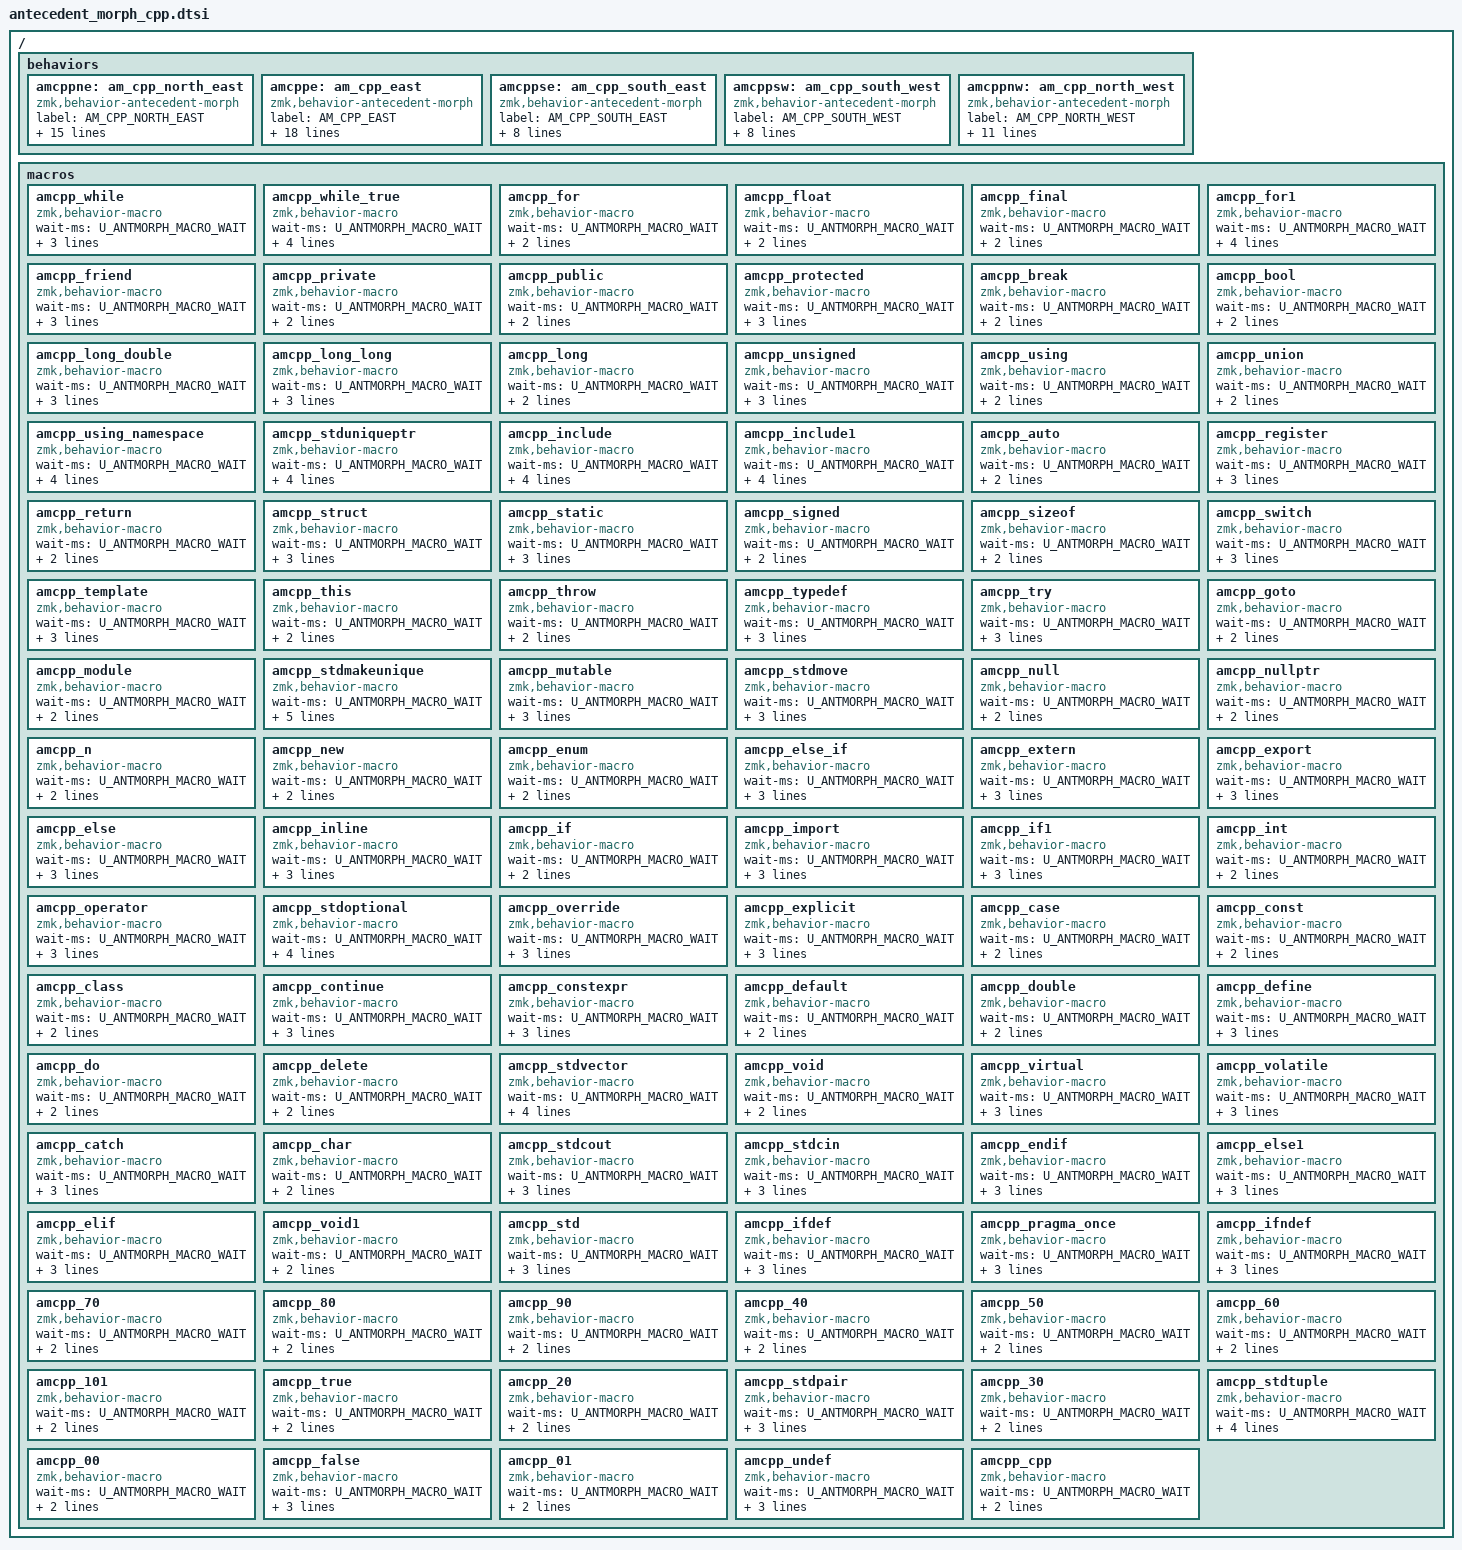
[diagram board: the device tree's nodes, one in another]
// Cpp schema version 1.2
// Automatically generated by ZMK Antecedent Morph Config Generator

/ {
    behaviors {
        // Base layer
        amcppne: am_cpp_north_east {
            compatible = "zmk,behavior-antecedent-morph";
            label = "AM_CPP_NORTH_EAST";
            #binding-cells = <0>;
            defaults = <&none>;
            bindings = <&amcpp_for>, <&amcpp_private>, <&amcpp_break>, <&amcpp_long_double>, <&amcpp_unsigned>, <&amcpp_include>, <&amcpp_register>, <&amcpp_struct>, <&amcpp_template>, <&amcpp_module>, <&amcpp_null>, <&amcpp_enum>, <&amcpp_inline>, <&amcpp_operator>, <&amcpp_case>, <&amcpp_default>, <&amcpp_stdvector>, <&kp N0>, <&amcpp_void1>, <&amcpp_ifdef>, <&amcpp_70>, <&amcpp_80>, <&amcpp_90>, <&amcpp_40>, <&amcpp_50>, <&amcpp_60>, <&amcpp_101>, <&amcpp_20>, <&amcpp_30>, <&amcpp_00>, <&amcpp_undef>;
            antecedents = <F P B L U APOS R S T M N E I O C D V DOT LPAR HASH N7 N8 N9 N4 N5 N6 N1 N2 N3 N0 SPACE>;
            max-delay-ms = <U_ANTMORPH_DELAY>;
        };
        amcppe: am_cpp_east {
            compatible = "zmk,behavior-antecedent-morph";
            label = "AM_CPP_EAST";
            #binding-cells = <0>;
            defaults = <&none>;
            bindings = <&amcpp_while>, <&amcpp_float>, <&amcpp_public>, <&amcpp_bool>, <&amcpp_long_long>, <&amcpp_using>, <&amcpp_auto>, <&amcpp_return>, <&amcpp_static>, <&amcpp_this>, <&amcpp_goto>, <&amcpp_stdmakeunique>, <&amcpp_nullptr>, <&amcpp_else_if>, <&amcpp_if>, <&amcpp_stdoptional>, <&amcpp_explicit>, <&amcpp_const>, <&amcpp_double>, <&amcpp_void>, <&amcpp_catch>, <&amcpp_stdcout>, <&amcpp_stdcin>, <&amcpp_else1>, <&kp RBRC>, <&kp RPAR>, <&kp EQUAL>, <&amcpp_std>, <&kp EQUAL>, <&kp EQUAL>, <&kp EQUAL>, <&kp EQUAL>, <&amcpp_pragma_once>, <&kp EQUAL>, <&kp EQUAL>, <&kp RBKT>, <&amcpp_true>, <&amcpp_stdpair>, <&amcpp_stdtuple>, <&amcpp_false>, <&kp EQUAL>, <&amcpp_cpp>;
            antecedents = <W F P B L U A R S T G M N E I O X C D V H COMMA DOT FSLH LBRC LPAR STAR COLON PRCNT CARET PLUS EXCL HASH PIPE AMPS LBKT N1 N2 N3 N0 MINUS SPACE>;
            max-delay-ms = <U_ANTMORPH_DELAY>;
        };
        amcppse: am_cpp_south_east {
            compatible = "zmk,behavior-antecedent-morph";
            label = "AM_CPP_SOUTH_EAST";
            #binding-cells = <0>;
            defaults = <&none>;
            bindings = <&amcpp_final>, <&amcpp_protected>, <&amcpp_union>, <&amcpp_signed>, <&amcpp_throw>, <&amcpp_mutable>, <&amcpp_extern>, <&amcpp_import>, <&amcpp_class>, <&amcpp_define>, <&amcpp_virtual>, <&amcpp_ifndef>, <&amcpp_01>;
            antecedents = <F P U S T M E I C D V HASH N0>;
            max-delay-ms = <U_ANTMORPH_DELAY>;
        };
        amcppsw: am_cpp_south_west {
            compatible = "zmk,behavior-antecedent-morph";
            label = "AM_CPP_SOUTH_WEST";
            #binding-cells = <0>;
            defaults = <&none>;
            bindings = <&amcpp_while_true>, <&amcpp_for1>, <&amcpp_using_namespace>, <&amcpp_sizeof>, <&amcpp_typedef>, <&amcpp_n>, <&amcpp_export>, <&amcpp_if1>, <&amcpp_continue>, <&amcpp_do>, <&amcpp_endif>, <&amcpp_elif>;
            antecedents = <W F U S T N E I C D DOT FSLH>;
            max-delay-ms = <U_ANTMORPH_DELAY>;
        };
        amcppnw: am_cpp_north_west {
            compatible = "zmk,behavior-antecedent-morph";
            label = "AM_CPP_NORTH_WEST";
            #binding-cells = <0>;
            defaults = <&none>;
            bindings = <&amcpp_friend>, <&amcpp_long>, <&amcpp_stduniqueptr>, <&amcpp_include1>, <&amcpp_switch>, <&amcpp_try>, <&amcpp_stdmove>, <&amcpp_new>, <&amcpp_else>, <&amcpp_int>, <&amcpp_override>, <&amcpp_constexpr>, <&amcpp_delete>, <&amcpp_volatile>, <&amcpp_char>, <&kp EQUAL>, <&kp EQUAL>, <&kp EQUAL>;
            antecedents = <F L U APOS S T M N E I O C D V H COMMA DOT FSLH>;
            max-delay-ms = <U_ANTMORPH_DELAY>;
        };
    };
    macros {
        amcpp_while: amcpp_while {
            compatible = "zmk,behavior-macro";
            #binding-cells = <0>;
            wait-ms = <U_ANTMORPH_MACRO_WAIT>;
            tap-ms = <U_ANTMORPH_MACRO_TAP>;
            // (w)hile (
            bindings = <&kp H &kp I &kp L &kp E &kp SPACE &kp LPAR>;
        };
        amcpp_while_true: amcpp_while_true {
            compatible = "zmk,behavior-macro";
            #binding-cells = <0>;
            wait-ms = <U_ANTMORPH_MACRO_WAIT>;
            tap-ms = <U_ANTMORPH_MACRO_TAP>;
            // (w)hile (true) {⏎
            bindings = <&kp H &kp I &kp L &kp E &kp SPACE &kp LPAR &kp T &kp R &kp U &kp E &kp RPAR &kp SPACE &kp LBRC &kp RET>;
        };
        amcpp_for: amcpp_for {
            compatible = "zmk,behavior-macro";
            #binding-cells = <0>;
            wait-ms = <U_ANTMORPH_MACRO_WAIT>;
            tap-ms = <U_ANTMORPH_MACRO_TAP>;
            // (f)or (
            bindings = <&kp O &kp R &kp SPACE &kp LPAR>;
        };
        amcpp_float: amcpp_float {
            compatible = "zmk,behavior-macro";
            #binding-cells = <0>;
            wait-ms = <U_ANTMORPH_MACRO_WAIT>;
            tap-ms = <U_ANTMORPH_MACRO_TAP>;
            // (f)loat
            bindings = <&kp L &kp O &kp A &kp T>;
        };
        amcpp_final: amcpp_final {
            compatible = "zmk,behavior-macro";
            #binding-cells = <0>;
            wait-ms = <U_ANTMORPH_MACRO_WAIT>;
            tap-ms = <U_ANTMORPH_MACRO_TAP>;
            // (f)inal
            bindings = <&kp I &kp N &kp A &kp L>;
        };
        amcpp_for1: amcpp_for1 {
            compatible = "zmk,behavior-macro";
            #binding-cells = <0>;
            wait-ms = <U_ANTMORPH_MACRO_WAIT>;
            tap-ms = <U_ANTMORPH_MACRO_TAP>;
            // (f)or (;;) {⏎
            bindings = <&kp O &kp R &kp SPACE &kp LPAR &kp SEMI &kp SEMI &kp RPAR &kp SPACE &kp LBRC &kp RET>;
        };
        amcpp_friend: amcpp_friend {
            compatible = "zmk,behavior-macro";
            #binding-cells = <0>;
            wait-ms = <U_ANTMORPH_MACRO_WAIT>;
            tap-ms = <U_ANTMORPH_MACRO_TAP>;
            // (f)riend 
            bindings = <&kp R &kp I &kp E &kp N &kp D &kp SPACE>;
        };
        amcpp_private: amcpp_private {
            compatible = "zmk,behavior-macro";
            #binding-cells = <0>;
            wait-ms = <U_ANTMORPH_MACRO_WAIT>;
            tap-ms = <U_ANTMORPH_MACRO_TAP>;
            // (p)rivate
            bindings = <&kp R &kp I &kp V &kp A &kp T &kp E>;
        };
        amcpp_public: amcpp_public {
            compatible = "zmk,behavior-macro";
            #binding-cells = <0>;
            wait-ms = <U_ANTMORPH_MACRO_WAIT>;
            tap-ms = <U_ANTMORPH_MACRO_TAP>;
            // (p)ublic
            bindings = <&kp U &kp B &kp L &kp I &kp C>;
        };
        amcpp_protected: amcpp_protected {
            compatible = "zmk,behavior-macro";
            #binding-cells = <0>;
            wait-ms = <U_ANTMORPH_MACRO_WAIT>;
            tap-ms = <U_ANTMORPH_MACRO_TAP>;
            // (p)rotected
            bindings = <&kp R &kp O &kp T &kp E &kp C &kp T &kp E &kp D>;
        };
        amcpp_break: amcpp_break {
            compatible = "zmk,behavior-macro";
            #binding-cells = <0>;
            wait-ms = <U_ANTMORPH_MACRO_WAIT>;
            tap-ms = <U_ANTMORPH_MACRO_TAP>;
            // (b)reak;
            bindings = <&kp R &kp E &kp A &kp K &kp SEMI>;
        };
        amcpp_bool: amcpp_bool {
            compatible = "zmk,behavior-macro";
            #binding-cells = <0>;
            wait-ms = <U_ANTMORPH_MACRO_WAIT>;
            tap-ms = <U_ANTMORPH_MACRO_TAP>;
            // (b)ool
            bindings = <&kp O &kp O &kp L>;
        };
        amcpp_long_double: amcpp_long_double {
            compatible = "zmk,behavior-macro";
            #binding-cells = <0>;
            wait-ms = <U_ANTMORPH_MACRO_WAIT>;
            tap-ms = <U_ANTMORPH_MACRO_TAP>;
            // (l)ong double
            bindings = <&kp O &kp N &kp G &kp SPACE &kp D &kp O &kp U &kp B &kp L &kp E>;
        };
        amcpp_long_long: amcpp_long_long {
            compatible = "zmk,behavior-macro";
            #binding-cells = <0>;
            wait-ms = <U_ANTMORPH_MACRO_WAIT>;
            tap-ms = <U_ANTMORPH_MACRO_TAP>;
            // (l)ong long
            bindings = <&kp O &kp N &kp G &kp SPACE &kp L &kp O &kp N &kp G>;
        };
        amcpp_long: amcpp_long {
            compatible = "zmk,behavior-macro";
            #binding-cells = <0>;
            wait-ms = <U_ANTMORPH_MACRO_WAIT>;
            tap-ms = <U_ANTMORPH_MACRO_TAP>;
            // (l)ong
            bindings = <&kp O &kp N &kp G>;
        };
        amcpp_unsigned: amcpp_unsigned {
            compatible = "zmk,behavior-macro";
            #binding-cells = <0>;
            wait-ms = <U_ANTMORPH_MACRO_WAIT>;
            tap-ms = <U_ANTMORPH_MACRO_TAP>;
            // (u)nsigned
            bindings = <&kp N &kp S &kp I &kp G &kp N &kp E &kp D>;
        };
        amcpp_using: amcpp_using {
            compatible = "zmk,behavior-macro";
            #binding-cells = <0>;
            wait-ms = <U_ANTMORPH_MACRO_WAIT>;
            tap-ms = <U_ANTMORPH_MACRO_TAP>;
            // (u)sing 
            bindings = <&kp S &kp I &kp N &kp G &kp SPACE>;
        };
        amcpp_union: amcpp_union {
            compatible = "zmk,behavior-macro";
            #binding-cells = <0>;
            wait-ms = <U_ANTMORPH_MACRO_WAIT>;
            tap-ms = <U_ANTMORPH_MACRO_TAP>;
            // (u)nion 
            bindings = <&kp N &kp I &kp O &kp N &kp SPACE>;
        };
        amcpp_using_namespace: amcpp_using_namespace {
            compatible = "zmk,behavior-macro";
            #binding-cells = <0>;
            wait-ms = <U_ANTMORPH_MACRO_WAIT>;
            tap-ms = <U_ANTMORPH_MACRO_TAP>;
            // (u)sing namespace 
            bindings = <&kp S &kp I &kp N &kp G &kp SPACE &kp N &kp A &kp M &kp E &kp S &kp P &kp A &kp C &kp E &kp SPACE>;
        };
        amcpp_stduniqueptr: amcpp_stduniqueptr {
            compatible = "zmk,behavior-macro";
            #binding-cells = <0>;
            wait-ms = <U_ANTMORPH_MACRO_WAIT>;
            tap-ms = <U_ANTMORPH_MACRO_TAP>;
            // [u]std::unique_ptr<
            bindings = <&kp BSPC &kp S &kp T &kp D &kp COLON &kp COLON &kp U &kp N &kp I &kp Q &kp U &kp E &kp UNDER &kp P &kp T &kp R &kp LT>;
        };
        amcpp_include: amcpp_include {
            compatible = "zmk,behavior-macro";
            #binding-cells = <0>;
            wait-ms = <U_ANTMORPH_MACRO_WAIT>;
            tap-ms = <U_ANTMORPH_MACRO_TAP>;
            // [‘]#include “”←
            bindings = <&kp BSPC &kp HASH &kp I &kp N &kp C &kp L &kp U &kp D &kp E &kp SPACE &kp DQT &kp DQT &kp LEFT>;
        };
        amcpp_include1: amcpp_include1 {
            compatible = "zmk,behavior-macro";
            #binding-cells = <0>;
            wait-ms = <U_ANTMORPH_MACRO_WAIT>;
            tap-ms = <U_ANTMORPH_MACRO_TAP>;
            // [‘]#include <>←
            bindings = <&kp BSPC &kp HASH &kp I &kp N &kp C &kp L &kp U &kp D &kp E &kp SPACE &kp LT &kp GT &kp LEFT>;
        };
        amcpp_auto: amcpp_auto {
            compatible = "zmk,behavior-macro";
            #binding-cells = <0>;
            wait-ms = <U_ANTMORPH_MACRO_WAIT>;
            tap-ms = <U_ANTMORPH_MACRO_TAP>;
            // (a)uto
            bindings = <&kp U &kp T &kp O>;
        };
        amcpp_register: amcpp_register {
            compatible = "zmk,behavior-macro";
            #binding-cells = <0>;
            wait-ms = <U_ANTMORPH_MACRO_WAIT>;
            tap-ms = <U_ANTMORPH_MACRO_TAP>;
            // (r)egister
            bindings = <&kp E &kp G &kp I &kp S &kp T &kp E &kp R>;
        };
        amcpp_return: amcpp_return {
            compatible = "zmk,behavior-macro";
            #binding-cells = <0>;
            wait-ms = <U_ANTMORPH_MACRO_WAIT>;
            tap-ms = <U_ANTMORPH_MACRO_TAP>;
            // (r)eturn
            bindings = <&kp E &kp T &kp U &kp R &kp N>;
        };
        amcpp_struct: amcpp_struct {
            compatible = "zmk,behavior-macro";
            #binding-cells = <0>;
            wait-ms = <U_ANTMORPH_MACRO_WAIT>;
            tap-ms = <U_ANTMORPH_MACRO_TAP>;
            // (s)truct 
            bindings = <&kp T &kp R &kp U &kp C &kp T &kp SPACE>;
        };
        amcpp_static: amcpp_static {
            compatible = "zmk,behavior-macro";
            #binding-cells = <0>;
            wait-ms = <U_ANTMORPH_MACRO_WAIT>;
            tap-ms = <U_ANTMORPH_MACRO_TAP>;
            // (s)tatic 
            bindings = <&kp T &kp A &kp T &kp I &kp C &kp SPACE>;
        };
        amcpp_signed: amcpp_signed {
            compatible = "zmk,behavior-macro";
            #binding-cells = <0>;
            wait-ms = <U_ANTMORPH_MACRO_WAIT>;
            tap-ms = <U_ANTMORPH_MACRO_TAP>;
            // (s)igned
            bindings = <&kp I &kp G &kp N &kp E &kp D>;
        };
        amcpp_sizeof: amcpp_sizeof {
            compatible = "zmk,behavior-macro";
            #binding-cells = <0>;
            wait-ms = <U_ANTMORPH_MACRO_WAIT>;
            tap-ms = <U_ANTMORPH_MACRO_TAP>;
            // (s)izeof
            bindings = <&kp I &kp Z &kp E &kp O &kp F>;
        };
        amcpp_switch: amcpp_switch {
            compatible = "zmk,behavior-macro";
            #binding-cells = <0>;
            wait-ms = <U_ANTMORPH_MACRO_WAIT>;
            tap-ms = <U_ANTMORPH_MACRO_TAP>;
            // (s)witch (
            bindings = <&kp W &kp I &kp T &kp C &kp H &kp SPACE &kp LPAR>;
        };
        amcpp_template: amcpp_template {
            compatible = "zmk,behavior-macro";
            #binding-cells = <0>;
            wait-ms = <U_ANTMORPH_MACRO_WAIT>;
            tap-ms = <U_ANTMORPH_MACRO_TAP>;
            // (t)emplate 
            bindings = <&kp E &kp M &kp P &kp L &kp A &kp T &kp E &kp SPACE>;
        };
        amcpp_this: amcpp_this {
            compatible = "zmk,behavior-macro";
            #binding-cells = <0>;
            wait-ms = <U_ANTMORPH_MACRO_WAIT>;
            tap-ms = <U_ANTMORPH_MACRO_TAP>;
            // (t)his
            bindings = <&kp H &kp I &kp S>;
        };
        amcpp_throw: amcpp_throw {
            compatible = "zmk,behavior-macro";
            #binding-cells = <0>;
            wait-ms = <U_ANTMORPH_MACRO_WAIT>;
            tap-ms = <U_ANTMORPH_MACRO_TAP>;
            // (t)hrow 
            bindings = <&kp H &kp R &kp O &kp W &kp SPACE>;
        };
        amcpp_typedef: amcpp_typedef {
            compatible = "zmk,behavior-macro";
            #binding-cells = <0>;
            wait-ms = <U_ANTMORPH_MACRO_WAIT>;
            tap-ms = <U_ANTMORPH_MACRO_TAP>;
            // (t)ypedef 
            bindings = <&kp Y &kp P &kp E &kp D &kp E &kp F &kp SPACE>;
        };
        amcpp_try: amcpp_try {
            compatible = "zmk,behavior-macro";
            #binding-cells = <0>;
            wait-ms = <U_ANTMORPH_MACRO_WAIT>;
            tap-ms = <U_ANTMORPH_MACRO_TAP>;
            // (t)ry {⏎
            bindings = <&kp R &kp Y &kp SPACE &kp LBRC &kp RET>;
        };
        amcpp_goto: amcpp_goto {
            compatible = "zmk,behavior-macro";
            #binding-cells = <0>;
            wait-ms = <U_ANTMORPH_MACRO_WAIT>;
            tap-ms = <U_ANTMORPH_MACRO_TAP>;
            // (g)oto 
            bindings = <&kp O &kp T &kp O &kp SPACE>;
        };
        amcpp_module: amcpp_module {
            compatible = "zmk,behavior-macro";
            #binding-cells = <0>;
            wait-ms = <U_ANTMORPH_MACRO_WAIT>;
            tap-ms = <U_ANTMORPH_MACRO_TAP>;
            // (m)odule
            bindings = <&kp O &kp D &kp U &kp L &kp E>;
        };
        amcpp_stdmakeunique: amcpp_stdmakeunique {
            compatible = "zmk,behavior-macro";
            #binding-cells = <0>;
            wait-ms = <U_ANTMORPH_MACRO_WAIT>;
            tap-ms = <U_ANTMORPH_MACRO_TAP>;
            // [m]std::make_unique<>(
            bindings = <&kp BSPC &kp S &kp T &kp D &kp COLON &kp COLON &kp M &kp A &kp K &kp E &kp UNDER &kp U &kp N &kp I &kp Q &kp U &kp E &kp LT &kp GT &kp LPAR>;
        };
        amcpp_mutable: amcpp_mutable {
            compatible = "zmk,behavior-macro";
            #binding-cells = <0>;
            wait-ms = <U_ANTMORPH_MACRO_WAIT>;
            tap-ms = <U_ANTMORPH_MACRO_TAP>;
            // (m)utable 
            bindings = <&kp U &kp T &kp A &kp B &kp L &kp E &kp SPACE>;
        };
        amcpp_stdmove: amcpp_stdmove {
            compatible = "zmk,behavior-macro";
            #binding-cells = <0>;
            wait-ms = <U_ANTMORPH_MACRO_WAIT>;
            tap-ms = <U_ANTMORPH_MACRO_TAP>;
            // [m]std::move(
            bindings = <&kp BSPC &kp S &kp T &kp D &kp COLON &kp COLON &kp M &kp O &kp V &kp E &kp LPAR>;
        };
        amcpp_null: amcpp_null {
            compatible = "zmk,behavior-macro";
            #binding-cells = <0>;
            wait-ms = <U_ANTMORPH_MACRO_WAIT>;
            tap-ms = <U_ANTMORPH_MACRO_TAP>;
            // (n)ULL
            bindings = <&kp LS(U) &kp LS(L) &kp LS(L)>;
        };
        amcpp_nullptr: amcpp_nullptr {
            compatible = "zmk,behavior-macro";
            #binding-cells = <0>;
            wait-ms = <U_ANTMORPH_MACRO_WAIT>;
            tap-ms = <U_ANTMORPH_MACRO_TAP>;
            // (n)ullptr
            bindings = <&kp U &kp L &kp L &kp P &kp T &kp R>;
        };
        amcpp_n: amcpp_n {
            compatible = "zmk,behavior-macro";
            #binding-cells = <0>;
            wait-ms = <U_ANTMORPH_MACRO_WAIT>;
            tap-ms = <U_ANTMORPH_MACRO_TAP>;
            // [n]\n
            bindings = <&kp BSPC &kp BSLH &kp N>;
        };
        amcpp_new: amcpp_new {
            compatible = "zmk,behavior-macro";
            #binding-cells = <0>;
            wait-ms = <U_ANTMORPH_MACRO_WAIT>;
            tap-ms = <U_ANTMORPH_MACRO_TAP>;
            // (n)ew
            bindings = <&kp E &kp W>;
        };
        amcpp_enum: amcpp_enum {
            compatible = "zmk,behavior-macro";
            #binding-cells = <0>;
            wait-ms = <U_ANTMORPH_MACRO_WAIT>;
            tap-ms = <U_ANTMORPH_MACRO_TAP>;
            // (e)num  
            bindings = <&kp N &kp U &kp M &kp SPACE &kp SPACE>;
        };
        amcpp_else_if: amcpp_else_if {
            compatible = "zmk,behavior-macro";
            #binding-cells = <0>;
            wait-ms = <U_ANTMORPH_MACRO_WAIT>;
            tap-ms = <U_ANTMORPH_MACRO_TAP>;
            // (e)lse if (
            bindings = <&kp L &kp S &kp E &kp SPACE &kp I &kp F &kp SPACE &kp LPAR>;
        };
        amcpp_extern: amcpp_extern {
            compatible = "zmk,behavior-macro";
            #binding-cells = <0>;
            wait-ms = <U_ANTMORPH_MACRO_WAIT>;
            tap-ms = <U_ANTMORPH_MACRO_TAP>;
            // (e)xtern 
            bindings = <&kp X &kp T &kp E &kp R &kp N &kp SPACE>;
        };
        amcpp_export: amcpp_export {
            compatible = "zmk,behavior-macro";
            #binding-cells = <0>;
            wait-ms = <U_ANTMORPH_MACRO_WAIT>;
            tap-ms = <U_ANTMORPH_MACRO_TAP>;
            // (e)xport 
            bindings = <&kp X &kp P &kp O &kp R &kp T &kp SPACE>;
        };
        amcpp_else: amcpp_else {
            compatible = "zmk,behavior-macro";
            #binding-cells = <0>;
            wait-ms = <U_ANTMORPH_MACRO_WAIT>;
            tap-ms = <U_ANTMORPH_MACRO_TAP>;
            // (e)lse {⏎
            bindings = <&kp L &kp S &kp E &kp SPACE &kp LBRC &kp RET>;
        };
        amcpp_inline: amcpp_inline {
            compatible = "zmk,behavior-macro";
            #binding-cells = <0>;
            wait-ms = <U_ANTMORPH_MACRO_WAIT>;
            tap-ms = <U_ANTMORPH_MACRO_TAP>;
            // (i)nline 
            bindings = <&kp N &kp L &kp I &kp N &kp E &kp SPACE>;
        };
        amcpp_if: amcpp_if {
            compatible = "zmk,behavior-macro";
            #binding-cells = <0>;
            wait-ms = <U_ANTMORPH_MACRO_WAIT>;
            tap-ms = <U_ANTMORPH_MACRO_TAP>;
            // (i)f (
            bindings = <&kp F &kp SPACE &kp LPAR>;
        };
        amcpp_import: amcpp_import {
            compatible = "zmk,behavior-macro";
            #binding-cells = <0>;
            wait-ms = <U_ANTMORPH_MACRO_WAIT>;
            tap-ms = <U_ANTMORPH_MACRO_TAP>;
            // (i)mport 
            bindings = <&kp M &kp P &kp O &kp R &kp T &kp SPACE>;
        };
        amcpp_if1: amcpp_if1 {
            compatible = "zmk,behavior-macro";
            #binding-cells = <0>;
            wait-ms = <U_ANTMORPH_MACRO_WAIT>;
            tap-ms = <U_ANTMORPH_MACRO_TAP>;
            // [i]#if 
            bindings = <&kp BSPC &kp HASH &kp I &kp F &kp SPACE>;
        };
        amcpp_int: amcpp_int {
            compatible = "zmk,behavior-macro";
            #binding-cells = <0>;
            wait-ms = <U_ANTMORPH_MACRO_WAIT>;
            tap-ms = <U_ANTMORPH_MACRO_TAP>;
            // (i)nt
            bindings = <&kp N &kp T>;
        };
        amcpp_operator: amcpp_operator {
            compatible = "zmk,behavior-macro";
            #binding-cells = <0>;
            wait-ms = <U_ANTMORPH_MACRO_WAIT>;
            tap-ms = <U_ANTMORPH_MACRO_TAP>;
            // (o)perator
            bindings = <&kp P &kp E &kp R &kp A &kp T &kp O &kp R>;
        };
        amcpp_stdoptional: amcpp_stdoptional {
            compatible = "zmk,behavior-macro";
            #binding-cells = <0>;
            wait-ms = <U_ANTMORPH_MACRO_WAIT>;
            tap-ms = <U_ANTMORPH_MACRO_TAP>;
            // [o]std::optional<
            bindings = <&kp BSPC &kp S &kp T &kp D &kp COLON &kp COLON &kp O &kp P &kp T &kp I &kp O &kp N &kp A &kp L &kp LT>;
        };
        amcpp_override: amcpp_override {
            compatible = "zmk,behavior-macro";
            #binding-cells = <0>;
            wait-ms = <U_ANTMORPH_MACRO_WAIT>;
            tap-ms = <U_ANTMORPH_MACRO_TAP>;
            // (o)verride
            bindings = <&kp V &kp E &kp R &kp R &kp I &kp D &kp E>;
        };
        amcpp_explicit: amcpp_explicit {
            compatible = "zmk,behavior-macro";
            #binding-cells = <0>;
            wait-ms = <U_ANTMORPH_MACRO_WAIT>;
            tap-ms = <U_ANTMORPH_MACRO_TAP>;
            // [x]explicit
            bindings = <&kp BSPC &kp E &kp X &kp P &kp L &kp I &kp C &kp I &kp T>;
        };
        amcpp_case: amcpp_case {
            compatible = "zmk,behavior-macro";
            #binding-cells = <0>;
            wait-ms = <U_ANTMORPH_MACRO_WAIT>;
            tap-ms = <U_ANTMORPH_MACRO_TAP>;
            // (c)ase 
            bindings = <&kp A &kp S &kp E &kp SPACE>;
        };
        amcpp_const: amcpp_const {
            compatible = "zmk,behavior-macro";
            #binding-cells = <0>;
            wait-ms = <U_ANTMORPH_MACRO_WAIT>;
            tap-ms = <U_ANTMORPH_MACRO_TAP>;
            // (c)onst
            bindings = <&kp O &kp N &kp S &kp T>;
        };
        amcpp_class: amcpp_class {
            compatible = "zmk,behavior-macro";
            #binding-cells = <0>;
            wait-ms = <U_ANTMORPH_MACRO_WAIT>;
            tap-ms = <U_ANTMORPH_MACRO_TAP>;
            // (c)lass 
            bindings = <&kp L &kp A &kp S &kp S &kp SPACE>;
        };
        amcpp_continue: amcpp_continue {
            compatible = "zmk,behavior-macro";
            #binding-cells = <0>;
            wait-ms = <U_ANTMORPH_MACRO_WAIT>;
            tap-ms = <U_ANTMORPH_MACRO_TAP>;
            // (c)ontinue;
            bindings = <&kp O &kp N &kp T &kp I &kp N &kp U &kp E &kp SEMI>;
        };
        amcpp_constexpr: amcpp_constexpr {
            compatible = "zmk,behavior-macro";
            #binding-cells = <0>;
            wait-ms = <U_ANTMORPH_MACRO_WAIT>;
            tap-ms = <U_ANTMORPH_MACRO_TAP>;
            // (c)onstexpr
            bindings = <&kp O &kp N &kp S &kp T &kp E &kp X &kp P &kp R>;
        };
        amcpp_default: amcpp_default {
            compatible = "zmk,behavior-macro";
            #binding-cells = <0>;
            wait-ms = <U_ANTMORPH_MACRO_WAIT>;
            tap-ms = <U_ANTMORPH_MACRO_TAP>;
            // (d)efault
            bindings = <&kp E &kp F &kp A &kp U &kp L &kp T>;
        };
        amcpp_double: amcpp_double {
            compatible = "zmk,behavior-macro";
            #binding-cells = <0>;
            wait-ms = <U_ANTMORPH_MACRO_WAIT>;
            tap-ms = <U_ANTMORPH_MACRO_TAP>;
            // (d)ouble
            bindings = <&kp O &kp U &kp B &kp L &kp E>;
        };
        amcpp_define: amcpp_define {
            compatible = "zmk,behavior-macro";
            #binding-cells = <0>;
            wait-ms = <U_ANTMORPH_MACRO_WAIT>;
            tap-ms = <U_ANTMORPH_MACRO_TAP>;
            // [d]#define 
            bindings = <&kp BSPC &kp HASH &kp D &kp E &kp F &kp I &kp N &kp E &kp SPACE>;
        };
        amcpp_do: amcpp_do {
            compatible = "zmk,behavior-macro";
            #binding-cells = <0>;
            wait-ms = <U_ANTMORPH_MACRO_WAIT>;
            tap-ms = <U_ANTMORPH_MACRO_TAP>;
            // (d)o {⏎
            bindings = <&kp O &kp SPACE &kp LBRC &kp RET>;
        };
        amcpp_delete: amcpp_delete {
            compatible = "zmk,behavior-macro";
            #binding-cells = <0>;
            wait-ms = <U_ANTMORPH_MACRO_WAIT>;
            tap-ms = <U_ANTMORPH_MACRO_TAP>;
            // (d)elete
            bindings = <&kp E &kp L &kp E &kp T &kp E>;
        };
        amcpp_stdvector: amcpp_stdvector {
            compatible = "zmk,behavior-macro";
            #binding-cells = <0>;
            wait-ms = <U_ANTMORPH_MACRO_WAIT>;
            tap-ms = <U_ANTMORPH_MACRO_TAP>;
            // [v]std::vector<
            bindings = <&kp BSPC &kp S &kp T &kp D &kp COLON &kp COLON &kp V &kp E &kp C &kp T &kp O &kp R &kp LT>;
        };
        amcpp_void: amcpp_void {
            compatible = "zmk,behavior-macro";
            #binding-cells = <0>;
            wait-ms = <U_ANTMORPH_MACRO_WAIT>;
            tap-ms = <U_ANTMORPH_MACRO_TAP>;
            // (v)oid
            bindings = <&kp O &kp I &kp D>;
        };
        amcpp_virtual: amcpp_virtual {
            compatible = "zmk,behavior-macro";
            #binding-cells = <0>;
            wait-ms = <U_ANTMORPH_MACRO_WAIT>;
            tap-ms = <U_ANTMORPH_MACRO_TAP>;
            // (v)irtual 
            bindings = <&kp I &kp R &kp T &kp U &kp A &kp L &kp SPACE>;
        };
        amcpp_volatile: amcpp_volatile {
            compatible = "zmk,behavior-macro";
            #binding-cells = <0>;
            wait-ms = <U_ANTMORPH_MACRO_WAIT>;
            tap-ms = <U_ANTMORPH_MACRO_TAP>;
            // (v)olatile
            bindings = <&kp O &kp L &kp A &kp T &kp I &kp L &kp E>;
        };
        amcpp_catch: amcpp_catch {
            compatible = "zmk,behavior-macro";
            #binding-cells = <0>;
            wait-ms = <U_ANTMORPH_MACRO_WAIT>;
            tap-ms = <U_ANTMORPH_MACRO_TAP>;
            // [h]catch (
            bindings = <&kp BSPC &kp C &kp A &kp T &kp C &kp H &kp SPACE &kp LPAR>;
        };
        amcpp_char: amcpp_char {
            compatible = "zmk,behavior-macro";
            #binding-cells = <0>;
            wait-ms = <U_ANTMORPH_MACRO_WAIT>;
            tap-ms = <U_ANTMORPH_MACRO_TAP>;
            // [h]char
            bindings = <&kp BSPC &kp C &kp H &kp A &kp R>;
        };
        amcpp_stdcout: amcpp_stdcout {
            compatible = "zmk,behavior-macro";
            #binding-cells = <0>;
            wait-ms = <U_ANTMORPH_MACRO_WAIT>;
            tap-ms = <U_ANTMORPH_MACRO_TAP>;
            // [,]std::cout
            bindings = <&kp BSPC &kp S &kp T &kp D &kp COLON &kp COLON &kp C &kp O &kp U &kp T>;
        };
        amcpp_stdcin: amcpp_stdcin {
            compatible = "zmk,behavior-macro";
            #binding-cells = <0>;
            wait-ms = <U_ANTMORPH_MACRO_WAIT>;
            tap-ms = <U_ANTMORPH_MACRO_TAP>;
            // [.]std::cin
            bindings = <&kp BSPC &kp S &kp T &kp D &kp COLON &kp COLON &kp C &kp I &kp N>;
        };
        amcpp_endif: amcpp_endif {
            compatible = "zmk,behavior-macro";
            #binding-cells = <0>;
            wait-ms = <U_ANTMORPH_MACRO_WAIT>;
            tap-ms = <U_ANTMORPH_MACRO_TAP>;
            // [.]#endif
            bindings = <&kp BSPC &kp HASH &kp E &kp N &kp D &kp I &kp F>;
        };
        amcpp_else1: amcpp_else1 {
            compatible = "zmk,behavior-macro";
            #binding-cells = <0>;
            wait-ms = <U_ANTMORPH_MACRO_WAIT>;
            tap-ms = <U_ANTMORPH_MACRO_TAP>;
            // [/]#else
            bindings = <&kp BSPC &kp HASH &kp E &kp L &kp S &kp E>;
        };
        amcpp_elif: amcpp_elif {
            compatible = "zmk,behavior-macro";
            #binding-cells = <0>;
            wait-ms = <U_ANTMORPH_MACRO_WAIT>;
            tap-ms = <U_ANTMORPH_MACRO_TAP>;
            // [/]#elif 
            bindings = <&kp BSPC &kp HASH &kp E &kp L &kp I &kp F &kp SPACE>;
        };

        amcpp_void1: amcpp_void1 {
            compatible = "zmk,behavior-macro";
            #binding-cells = <0>;
            wait-ms = <U_ANTMORPH_MACRO_WAIT>;
            tap-ms = <U_ANTMORPH_MACRO_TAP>;
            // (()void)
            bindings = <&kp V &kp O &kp I &kp D &kp RPAR>;
        };

        amcpp_std: amcpp_std {
            compatible = "zmk,behavior-macro";
            #binding-cells = <0>;
            wait-ms = <U_ANTMORPH_MACRO_WAIT>;
            tap-ms = <U_ANTMORPH_MACRO_TAP>;
            // [:]std::
            bindings = <&kp BSPC &kp S &kp T &kp D &kp COLON &kp COLON>;
        };




        amcpp_ifdef: amcpp_ifdef {
            compatible = "zmk,behavior-macro";
            #binding-cells = <0>;
            wait-ms = <U_ANTMORPH_MACRO_WAIT>;
            tap-ms = <U_ANTMORPH_MACRO_TAP>;
            // (#)ifdef 
            bindings = <&kp I &kp F &kp D &kp E &kp F &kp SPACE>;
        };
        amcpp_pragma_once: amcpp_pragma_once {
            compatible = "zmk,behavior-macro";
            #binding-cells = <0>;
            wait-ms = <U_ANTMORPH_MACRO_WAIT>;
            tap-ms = <U_ANTMORPH_MACRO_TAP>;
            // (#)pragma once
            bindings = <&kp P &kp R &kp A &kp G &kp M &kp A &kp SPACE &kp O &kp N &kp C &kp E>;
        };
        amcpp_ifndef: amcpp_ifndef {
            compatible = "zmk,behavior-macro";
            #binding-cells = <0>;
            wait-ms = <U_ANTMORPH_MACRO_WAIT>;
            tap-ms = <U_ANTMORPH_MACRO_TAP>;
            // (#)ifndef 
            bindings = <&kp I &kp F &kp N &kp D &kp E &kp F &kp SPACE>;
        };



        amcpp_70: amcpp_70 {
            compatible = "zmk,behavior-macro";
            #binding-cells = <0>;
            wait-ms = <U_ANTMORPH_MACRO_WAIT>;
            tap-ms = <U_ANTMORPH_MACRO_TAP>;
            // (7).0
            bindings = <&kp DOT &kp N0>;
        };
        amcpp_80: amcpp_80 {
            compatible = "zmk,behavior-macro";
            #binding-cells = <0>;
            wait-ms = <U_ANTMORPH_MACRO_WAIT>;
            tap-ms = <U_ANTMORPH_MACRO_TAP>;
            // (8).0
            bindings = <&kp DOT &kp N0>;
        };
        amcpp_90: amcpp_90 {
            compatible = "zmk,behavior-macro";
            #binding-cells = <0>;
            wait-ms = <U_ANTMORPH_MACRO_WAIT>;
            tap-ms = <U_ANTMORPH_MACRO_TAP>;
            // (9).0
            bindings = <&kp DOT &kp N0>;
        };
        amcpp_40: amcpp_40 {
            compatible = "zmk,behavior-macro";
            #binding-cells = <0>;
            wait-ms = <U_ANTMORPH_MACRO_WAIT>;
            tap-ms = <U_ANTMORPH_MACRO_TAP>;
            // (4).0
            bindings = <&kp DOT &kp N0>;
        };
        amcpp_50: amcpp_50 {
            compatible = "zmk,behavior-macro";
            #binding-cells = <0>;
            wait-ms = <U_ANTMORPH_MACRO_WAIT>;
            tap-ms = <U_ANTMORPH_MACRO_TAP>;
            // (5).0
            bindings = <&kp DOT &kp N0>;
        };
        amcpp_60: amcpp_60 {
            compatible = "zmk,behavior-macro";
            #binding-cells = <0>;
            wait-ms = <U_ANTMORPH_MACRO_WAIT>;
            tap-ms = <U_ANTMORPH_MACRO_TAP>;
            // (6).0
            bindings = <&kp DOT &kp N0>;
        };
        amcpp_101: amcpp_101 {
            compatible = "zmk,behavior-macro";
            #binding-cells = <0>;
            wait-ms = <U_ANTMORPH_MACRO_WAIT>;
            tap-ms = <U_ANTMORPH_MACRO_TAP>;
            // (1).0
            bindings = <&kp DOT &kp N0>;
        };
        amcpp_true: amcpp_true {
            compatible = "zmk,behavior-macro";
            #binding-cells = <0>;
            wait-ms = <U_ANTMORPH_MACRO_WAIT>;
            tap-ms = <U_ANTMORPH_MACRO_TAP>;
            // [1]true
            bindings = <&kp BSPC &kp T &kp R &kp U &kp E>;
        };
        amcpp_20: amcpp_20 {
            compatible = "zmk,behavior-macro";
            #binding-cells = <0>;
            wait-ms = <U_ANTMORPH_MACRO_WAIT>;
            tap-ms = <U_ANTMORPH_MACRO_TAP>;
            // (2).0
            bindings = <&kp DOT &kp N0>;
        };
        amcpp_stdpair: amcpp_stdpair {
            compatible = "zmk,behavior-macro";
            #binding-cells = <0>;
            wait-ms = <U_ANTMORPH_MACRO_WAIT>;
            tap-ms = <U_ANTMORPH_MACRO_TAP>;
            // [2]std::pair<
            bindings = <&kp BSPC &kp S &kp T &kp D &kp COLON &kp COLON &kp P &kp A &kp I &kp R &kp LT>;
        };
        amcpp_30: amcpp_30 {
            compatible = "zmk,behavior-macro";
            #binding-cells = <0>;
            wait-ms = <U_ANTMORPH_MACRO_WAIT>;
            tap-ms = <U_ANTMORPH_MACRO_TAP>;
            // (3).0
            bindings = <&kp DOT &kp N0>;
        };
        amcpp_stdtuple: amcpp_stdtuple {
            compatible = "zmk,behavior-macro";
            #binding-cells = <0>;
            wait-ms = <U_ANTMORPH_MACRO_WAIT>;
            tap-ms = <U_ANTMORPH_MACRO_TAP>;
            // [3]std::tuple<
            bindings = <&kp BSPC &kp S &kp T &kp D &kp COLON &kp COLON &kp T &kp U &kp P &kp L &kp E &kp LT>;
        };
        amcpp_00: amcpp_00 {
            compatible = "zmk,behavior-macro";
            #binding-cells = <0>;
            wait-ms = <U_ANTMORPH_MACRO_WAIT>;
            tap-ms = <U_ANTMORPH_MACRO_TAP>;
            // (0).0
            bindings = <&kp DOT &kp N0>;
        };
        amcpp_false: amcpp_false {
            compatible = "zmk,behavior-macro";
            #binding-cells = <0>;
            wait-ms = <U_ANTMORPH_MACRO_WAIT>;
            tap-ms = <U_ANTMORPH_MACRO_TAP>;
            // [0]false
            bindings = <&kp BSPC &kp F &kp A &kp L &kp S &kp E>;
        };
        amcpp_01: amcpp_01 {
            compatible = "zmk,behavior-macro";
            #binding-cells = <0>;
            wait-ms = <U_ANTMORPH_MACRO_WAIT>;
            tap-ms = <U_ANTMORPH_MACRO_TAP>;
            // [0]\0
            bindings = <&kp BSPC &kp BSLH &kp N0>;
        };

        amcpp_undef: amcpp_undef {
            compatible = "zmk,behavior-macro";
            #binding-cells = <0>;
            wait-ms = <U_ANTMORPH_MACRO_WAIT>;
            tap-ms = <U_ANTMORPH_MACRO_TAP>;
            // [ ]#undef 
            bindings = <&kp BSPC &kp HASH &kp U &kp N &kp D &kp E &kp F &kp SPACE>;
        };
        amcpp_cpp: amcpp_cpp {
            compatible = "zmk,behavior-macro";
            #binding-cells = <0>;
            wait-ms = <U_ANTMORPH_MACRO_WAIT>;
            tap-ms = <U_ANTMORPH_MACRO_TAP>;
            // [ ]Cpp
            bindings = <&kp BSPC &kp LS(C) &kp P &kp P>;
        };
    };
};
